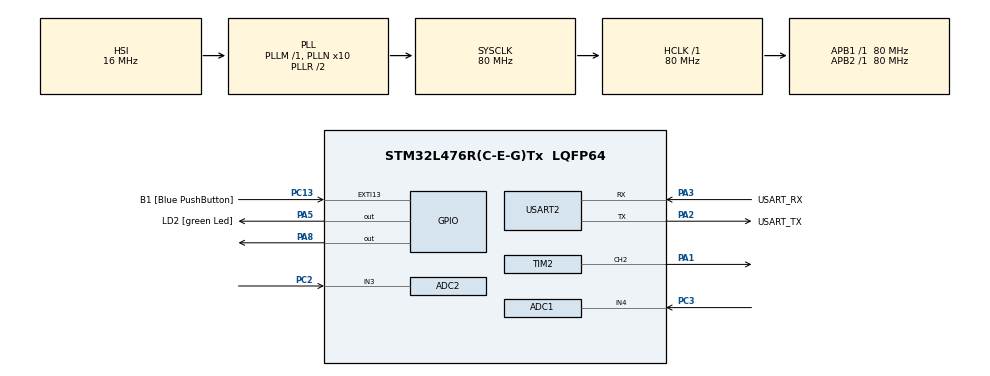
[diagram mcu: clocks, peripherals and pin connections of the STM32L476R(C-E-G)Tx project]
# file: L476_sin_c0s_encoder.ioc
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ADC1.ClockPrescaler=ADC_CLOCK_ASYNC_DIV1
ADC1.ContinuousConvMode=DISABLE
ADC1.DataAlign=ADC_DATAALIGN_RIGHT
ADC1.EnableInjectedConversion=ENABLE
ADC1.EnableRegularConversion=DISABLE
ADC1.ExternalTrigInjecConv=ADC_EXTERNALTRIGINJEC_T2_TRGO
ADC1.InjMonitoredBy-1\#ChannelInjectedConversion=__NULL
ADC1.InjNumberOfConversion=1
ADC1.InjectedChannel-1\#ChannelInjectedConversion=ADC_CHANNEL_4
ADC1.InjectedConvMode=None
ADC1.InjectedOffsetNumber-1\#ChannelInjectedConversion=ADC_OFFSET_NONE
ADC1.InjectedRank-1\#ChannelInjectedConversion=1
ADC1.InjectedSamplingTime-1\#ChannelInjectedConversion=ADC_SAMPLETIME_6CYCLES_5
ADC1.Rank2_Channel=ADC_CHANNEL_3
ADC1.master=1
ADC2.EnableInjectedConversion=ENABLE
ADC2.EnableRegularConversion=DISABLE
ADC2.ExternalTrigInjecConv=ADC_EXTERNALTRIGINJEC_T2_TRGO
ADC2.InjMonitoredBy-2\#ChannelInjectedConversion=__NULL
ADC2.InjNumberOfConversion=1
ADC2.InjectedChannel-2\#ChannelInjectedConversion=ADC_CHANNEL_3
ADC2.InjectedOffsetNumber-2\#ChannelInjectedConversion=ADC_OFFSET_NONE
ADC2.InjectedRank-2\#ChannelInjectedConversion=1
ADC2.InjectedSamplingTime-2\#ChannelInjectedConversion=ADC_SAMPLETIME_6CYCLES_5
ADC2.Rank1_Channel=ADC_CHANNEL_3
Mcu.Family=STM32L4
Mcu.Name=STM32L476R(C-E-G)Tx
Mcu.Package=LQFP64
NVIC.ADC1_2_IRQn=true\:0\:0\:false\:false\:true\:true\:true\:true
NVIC.PriorityGroup=NVIC_PRIORITYGROUP_4
PA1.Signal=S_TIM2_CH2
PA13\ (JTMS-SWDIO).GPIO_Label=TMS
PA13\ (JTMS-SWDIO).Mode=Serial_Wire
PA13\ (JTMS-SWDIO).Signal=SYS_JTMS-SWDIO
PA14\ (JTCK-SWCLK).GPIO_Label=TCK
PA14\ (JTCK-SWCLK).Mode=Serial_Wire
PA14\ (JTCK-SWCLK).Signal=SYS_JTCK-SWCLK
PA2.GPIO_Label=USART_TX
PA2.GPIO_Mode=GPIO_MODE_AF_PP
PA2.GPIO_PuPd=GPIO_NOPULL
PA2.GPIO_Speed=GPIO_SPEED_FREQ_VERY_HIGH
PA2.Mode=Asynchronous
PA2.Signal=USART2_TX
PA3.GPIO_Label=USART_RX
PA3.GPIO_Mode=GPIO_MODE_AF_PP
PA3.GPIO_PuPd=GPIO_NOPULL
PA3.GPIO_Speed=GPIO_SPEED_FREQ_VERY_HIGH
PA3.Mode=Asynchronous
PA3.Signal=USART2_RX
PA5.GPIO_Label=LD2 [green Led]
PA5.GPIO_ModeDefaultOutputPP=GPIO_MODE_OUTPUT_PP
PA5.GPIO_PuPd=GPIO_NOPULL
PA5.GPIO_Speed=GPIO_SPEED_FREQ_LOW
PA5.Signal=GPIO_Output
PA8.Signal=GPIO_Output
PB3\ (JTDO-TRACESWO).GPIO_Label=SWO
PB3\ (JTDO-TRACESWO).Signal=SYS_JTDO-SWO
PC13.GPIO_Label=B1 [Blue PushButton]
PC13.GPIO_ModeDefaultEXTI=GPIO_MODE_IT_FALLING
PC13.GPIO_PuPd=GPIO_NOPULL
PC13.Signal=GPXTI13
PC14-OSC32_IN\ (PC14).Mode=LSE-External-Oscillator
PC14-OSC32_IN\ (PC14).Signal=RCC_OSC32_IN
PC15-OSC32_OUT\ (PC15).Mode=LSE-External-Oscillator
PC15-OSC32_OUT\ (PC15).Signal=RCC_OSC32_OUT
PC2.Signal=ADCx_IN3
PC3.Signal=ADCx_IN4
PH0-OSC_IN\ (PH0).Signal=RCC_OSC_IN
PH1-OSC_OUT\ (PH1).Signal=RCC_OSC_OUT
ProjectManager.HeapSize=0x200
ProjectManager.StackSize=0x400
ProjectManager.TargetToolchain=STM32CubeIDE
RCC.ADCFreq_Value=64000000
RCC.AHBFreq_Value=80000000
RCC.APB1Freq_Value=80000000
RCC.APB1TimFreq_Value=80000000
RCC.APB2Freq_Value=80000000
RCC.APB2TimFreq_Value=80000000
RCC.CortexFreq_Value=80000000
RCC.HCLKFreq_Value=80000000
RCC.HSE_VALUE=8000000
RCC.HSI_VALUE=16000000
RCC.MSI_VALUE=4000000
RCC.PLLN=10
RCC.PLLSourceVirtual=RCC_PLLSOURCE_HSI
RCC.PREFETCH_ENABLE=1
RCC.SYSCLKFreq_VALUE=80000000
RCC.SYSCLKSource=RCC_SYSCLKSOURCE_PLLCLK
RCC.USBFreq_Value=64000000
RCC.VCOOutputFreq_Value=160000000
SH.ADCx_IN3.0=ADC2_IN3,IN3-Single-Ended
SH.ADCx_IN4.0=ADC1_IN4,IN4-Single-Ended
SH.S_TIM2_CH2.0=TIM2_CH2,PWM Generation2 CH2
TIM2.Channel-Output\ Compare1\ No\ Output=TIM_CHANNEL_1
TIM2.Channel-PWM\ Generation2\ CH2=TIM_CHANNEL_2
TIM2.CounterMode=TIM_COUNTERMODE_CENTERALIGNED1
TIM2.Period=4095
TIM2.Pulse-PWM\ Generation2\ CH2=2024
TIM2.TIM_MasterOutputTrigger=TIM_TRGO_OC1
USART2.VirtualMode-Asynchronous=VM_ASYNC
VP_TIM2_VS_no_output1.Mode=Output Compare1 No Output
board=NUCLEO-L476RG

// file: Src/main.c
/* USER CODE BEGIN Header */
/**
  ******************************************************************************
  * @file           : main.c
  * @brief          : Main program body
  ******************************************************************************
  * @attention
  *
  * Copyright (c) 2024 STMicroelectronics.
  * All rights reserved.
  *
  * This software is licensed under terms that can be found in the LICENSE file
  * in the root directory of this software component.
  * If no LICENSE file comes with this software, it is provided AS-IS.
  *
  ******************************************************************************
  */
/* USER CODE END Header */
#include "main.h"
#include "adc.h"
#include "tim.h"
#include "usart.h"
#include "gpio.h"
#include "enc_sincos.h"

/* USER CODE BEGIN PTD */
EncSinCosConfigT enc_cfg;
/* USER CODE END PTD */

void SystemClock_Config(void);
void PeriphCommonClock_Config(void);

int main(void)
{

  /* MCU Configuration--------------------------------------------------------*/

  /* Reset of all peripherals, Initializes the Flash interface and the Systick. */
  HAL_Init();

  /* Configure the system clock */
  SystemClock_Config();

/* Configure the peripherals common clocks */
  PeriphCommonClock_Config();

  /* Initialize all configured peripherals */
  MX_GPIO_Init();
  MX_USART2_UART_Init();
  MX_ADC1_Init();
  MX_TIM2_Init();
  MX_ADC2_Init();
  /* USER CODE BEGIN 2 */
  enc_sincos_get_defaults( &enc_cfg );
  HAL_TIM_PWM_Start( &htim2, TIM_CHANNEL_2 );	// Start PWM: TIM2 (CH2)
  HAL_TIM_OC_Start( &htim2, TIM_CHANNEL_1 );	// Start Output Compare (CH1)
  TIM2->CCR1 = 1;								// // Set The OC1 Trigger Point To The Middle of The PWM Waveform
//  HAL_ADC_Start(&hadc1);
  HAL_ADCEx_Calibration_Start( &hadc1, ADC_SINGLE_ENDED );
  HAL_ADCEx_InjectedStart_IT( &hadc1 ); 		// Start ADC Conversion (Injected Channel, Tim2-PWM-Triggered, Interrupt Mode)
  HAL_ADCEx_Calibration_Start( &hadc2, ADC_SINGLE_ENDED );
  HAL_ADCEx_InjectedStart_IT( &hadc2 ); 		// Start ADC Conversion (Injected Channel, Tim2-PWM-Triggered, Interrupt Mode)

  /* USER CODE END 2 */

  /* Infinite loop */
  while (1)
  {

  }
}

void SystemClock_Config(void)
{
  RCC_OscInitTypeDef RCC_OscInitStruct = {0};
  RCC_ClkInitTypeDef RCC_ClkInitStruct = {0};

  /** Configure the main internal regulator output voltage
  */
  if (HAL_PWREx_ControlVoltageScaling(PWR_REGULATOR_VOLTAGE_SCALE1) != HAL_OK)
  {
    Error_Handler();
  }

  /** Initializes the RCC Oscillators according to the specified parameters
  * in the RCC_OscInitTypeDef structure.
  */
  RCC_OscInitStruct.OscillatorType = RCC_OSCILLATORTYPE_HSI;
  RCC_OscInitStruct.HSIState = RCC_HSI_ON;
  RCC_OscInitStruct.HSICalibrationValue = RCC_HSICALIBRATION_DEFAULT;
  RCC_OscInitStruct.PLL.PLLState = RCC_PLL_ON;
  RCC_OscInitStruct.PLL.PLLSource = RCC_PLLSOURCE_HSI;
  RCC_OscInitStruct.PLL.PLLM = 1;
  RCC_OscInitStruct.PLL.PLLN = 10;
  RCC_OscInitStruct.PLL.PLLP = RCC_PLLP_DIV7;
  RCC_OscInitStruct.PLL.PLLQ = RCC_PLLQ_DIV2;
  RCC_OscInitStruct.PLL.PLLR = RCC_PLLR_DIV2;
  if (HAL_RCC_OscConfig(&RCC_OscInitStruct) != HAL_OK)
  {
    Error_Handler();
  }

  /** Initializes the CPU, AHB and APB buses clocks
  */
  RCC_ClkInitStruct.ClockType = RCC_CLOCKTYPE_HCLK|RCC_CLOCKTYPE_SYSCLK
                              |RCC_CLOCKTYPE_PCLK1|RCC_CLOCKTYPE_PCLK2;
  RCC_ClkInitStruct.SYSCLKSource = RCC_SYSCLKSOURCE_PLLCLK;
  RCC_ClkInitStruct.AHBCLKDivider = RCC_SYSCLK_DIV1;
  RCC_ClkInitStruct.APB1CLKDivider = RCC_HCLK_DIV1;
  RCC_ClkInitStruct.APB2CLKDivider = RCC_HCLK_DIV1;

  if (HAL_RCC_ClockConfig(&RCC_ClkInitStruct, FLASH_LATENCY_4) != HAL_OK)
  {
    Error_Handler();
  }
}

void PeriphCommonClock_Config(void)
{
  RCC_PeriphCLKInitTypeDef PeriphClkInit = {0};

  /** Initializes the peripherals clock
  */
  PeriphClkInit.PeriphClockSelection = RCC_PERIPHCLK_ADC;
  PeriphClkInit.AdcClockSelection = RCC_ADCCLKSOURCE_PLLSAI1;
  PeriphClkInit.PLLSAI1.PLLSAI1Source = RCC_PLLSOURCE_HSI;
  PeriphClkInit.PLLSAI1.PLLSAI1M = 1;
  PeriphClkInit.PLLSAI1.PLLSAI1N = 8;
  PeriphClkInit.PLLSAI1.PLLSAI1P = RCC_PLLP_DIV7;
  PeriphClkInit.PLLSAI1.PLLSAI1Q = RCC_PLLQ_DIV2;
  PeriphClkInit.PLLSAI1.PLLSAI1R = RCC_PLLR_DIV2;
  PeriphClkInit.PLLSAI1.PLLSAI1ClockOut = RCC_PLLSAI1_ADC1CLK;
  if (HAL_RCCEx_PeriphCLKConfig(&PeriphClkInit) != HAL_OK)
  {
    Error_Handler();
  }
}

void Error_Handler(void)
{
  __disable_irq();
  while (1)
  {
  }
}
